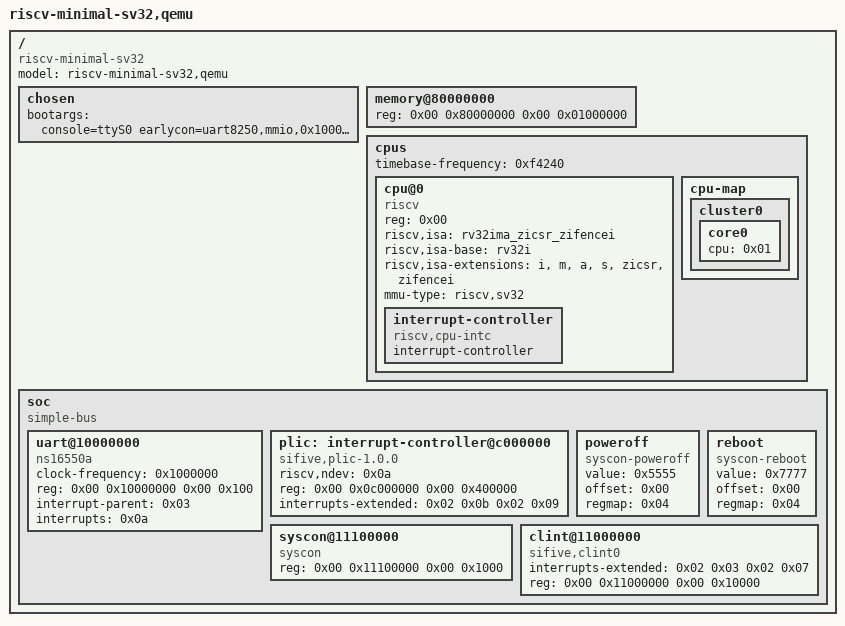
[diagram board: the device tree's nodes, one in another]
/dts-v1/;

/ {
        #address-cells = <0x02>;
        #size-cells = <0x02>;
        compatible = "riscv-minimal-sv32";
        model = "riscv-minimal-sv32,qemu";

        chosen {
                bootargs = "console=ttyS0 earlycon=uart8250,mmio,0x10000000,16550a";
        };

        memory@80000000 {
                device_type = "memory";
                reg = <0x00 0x80000000 0x00 0x01000000>;
        };

        cpus {
                #address-cells = <0x01>;
                #size-cells = <0x00>;
                timebase-frequency = <0xf4240>;

                cpu@0 {
                        phandle = <0x01>;
                        device_type = "cpu";
                        reg = <0x00>;
                        status = "okay";
                        compatible = "riscv";
                        riscv,isa = "rv32ima_zicsr_zifencei";
                        riscv,isa-base = "rv32i";
                        riscv,isa-extensions = "i", "m", "a", "s", "zicsr", "zifencei";
                        mmu-type = "riscv,sv32";

                        interrupt-controller {
                                #interrupt-cells = <0x01>;
                                interrupt-controller;
                                compatible = "riscv,cpu-intc";
                                phandle = <0x02>;
                        };
                };

                cpu-map {

                        cluster0 {

                                core0 {
                                        cpu = <0x01>;
                                };
                        };
                };
        };

        soc {
                #address-cells = <0x02>;
                #size-cells = <0x02>;
                compatible = "simple-bus";
                ranges;

                uart@10000000 {
                        clock-frequency = <0x1000000>;
                        reg = <0x00 0x10000000 0x00 0x100>;
                        compatible = "ns16550a";
                        interrupt-parent = <0x03>;
                        interrupts = <0x0a>;
                };

                plic: interrupt-controller@c000000 {
                        #interrupt-cells = <0x01>;
                        #address-cells = <0x00>;
                        phandle = <0x03>;
                        riscv,ndev = <0x0a>;
                        reg = <0x00 0x0c000000 0x00 0x400000>;
                        interrupts-extended = <0x02 0x0b 0x02 0x09>;
                        compatible = "sifive,plic-1.0.0", "riscv,plic0";
                };

                poweroff {
                        value = <0x5555>;
                        offset = <0x00>;
                        regmap = <0x04>;
                        compatible = "syscon-poweroff";
                };

                reboot {
                        value = <0x7777>;
                        offset = <0x00>;
                        regmap = <0x04>;
                        compatible = "syscon-reboot";
                };

                syscon@11100000 {
                        phandle = <0x04>;
                        reg = <0x00 0x11100000 0x00 0x1000>;
                        compatible = "syscon";
                };

                clint@11000000 {
                        interrupts-extended = <0x02 0x03 0x02 0x07>;
                        reg = <0x00 0x11000000 0x00 0x10000>;
                        compatible = "sifive,clint0", "riscv,clint0";
                };
        };
};
